# WBZ450 register map
Vendor: Microchip
Registers are 32-bit, read-write, reset 0x0 unless marked. A register's access mark holds for its fields unless they carry their own. Addresses are absolute, and some are shared; only a register's first bit layout is shown; [hi:lo] are bit positions; {n}, {i} and the like mark numbered series; 'fields as' and 'values as' point back to an identical list.

## DMAC
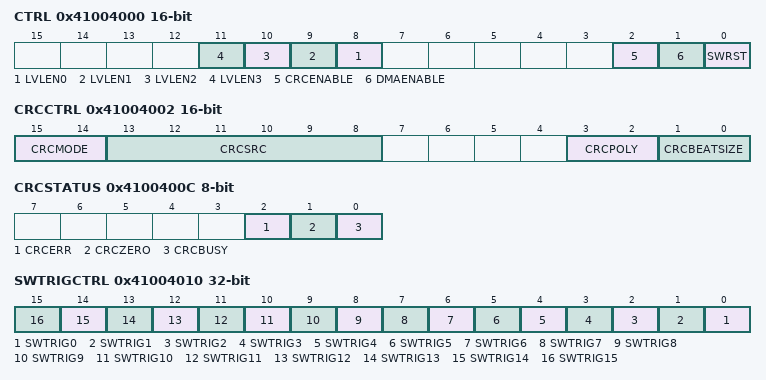
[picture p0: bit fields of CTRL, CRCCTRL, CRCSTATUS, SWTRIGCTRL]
0x41004000 CTRL 16-bit
  [n+8] LVLEN{n} (n=0..3) — Priority Level {n} Enable
  [2] CRCENABLE
  [1] DMAENABLE
  [0] SWRST — Software Reset
0x41004002 CRCCTRL 16-bit
  [15:14] CRCMODE — CRC Operating Mode
    0=DEFAULT (Default operating mode); 2=CRCMON (Memory CRC monitor operating mode); 3=CRCGEN (Memory CRC generation operating mode)
  [13:8] CRCSRC — CRC Input Source
    0=DISABLE (CRC Disabled); 1=IO (I/O interface)
  [3:2] CRCPOLY — CRC Polynomial Type
    0=CRC16 (CRC-16 (CRC-CCITT)); 1=CRC32 (CRC32 (IEEE 802.3))
  [1:0] CRCBEATSIZE
    0=BYTE (8-bit bus transfer); 1=HWORD (16-bit bus transfer); 2=WORD (32-bit bus transfer)
0x41004004 CRCDATAIN
  [31:0] CRCDATAIN — CRC Data Input
0x41004008 CRCCHKSUM
  [31:0] CRCCHKSUM — CRC Checksum
0x4100400C CRCSTATUS 8-bit
  [2] CRCERR — CRC Error
  [1] CRCZERO
  [0] CRCBUSY — CRC Module Busy
0x4100400D DBGCTRL 8-bit
  [0] DBGRUN — Debug Run
0x41004010 SWTRIGCTRL
  [n] SWTRIG{n} (n=0..15) — Channel {n} Software Trigger
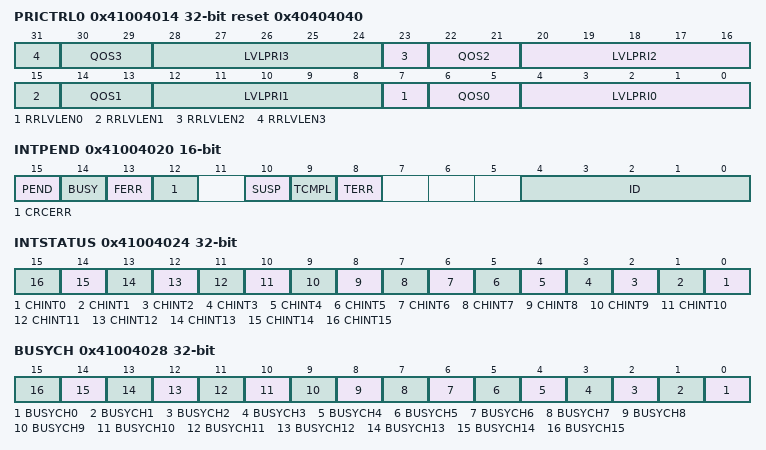
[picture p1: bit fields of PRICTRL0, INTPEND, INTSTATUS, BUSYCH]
0x41004014 PRICTRL0 reset 0x40404040
  [8n+7] RRLVLEN{n} (n=0..3) — Level {n} Round-Robin Scheduling Enable
  [8n+6:8n+5] QOS{n} (n=0..3) — Level {n} Quality of Service
    0=REGULAR (Regular delivery); 1=SHORTAGE (Bandwidth shortage); 2=SENSITIVE (Latency sensitive); 3=CRITICAL (Latency critical)
  [8n+4:8n] LVLPRI{n} (n=0..3) — Level {n} Channel Priority Number
0x41004020 INTPEND 16-bit
  [15] PEND — Pending
  [14] BUSY
  [13] FERR — Fetch Error
  [12] CRCERR — CRC Error
  [10] SUSP — Channel Suspend
  [9] TCMPL — Transfer Complete
  [8] TERR — Transfer Error
  [4:0] ID — Channel ID
0x41004024 INTSTATUS ro
  [n] CHINT{n} (n=0..15) — Channel {n} Pending Interrupt
0x41004028 BUSYCH ro
  [n] BUSYCH{n} (n=0..15) — Busy Channel {n}
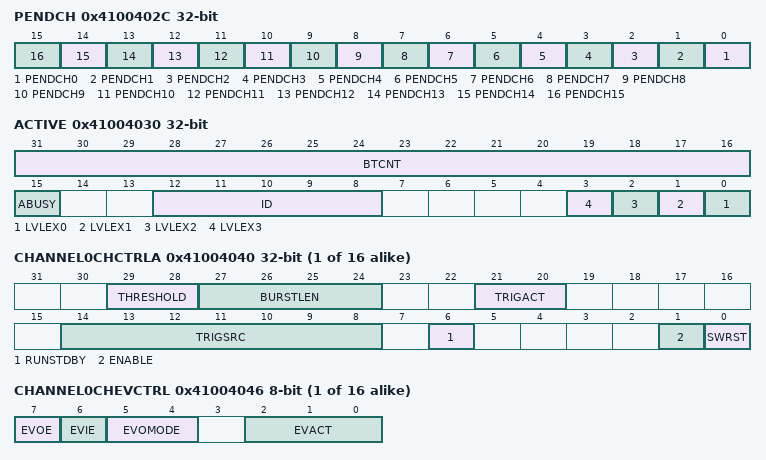
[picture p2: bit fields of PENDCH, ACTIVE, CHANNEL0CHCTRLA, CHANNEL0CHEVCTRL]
0x4100402C PENDCH ro
  [n] PENDCH{n} (n=0..15) — Pending Channel {n}
0x41004030 ACTIVE ro
  [31:16] BTCNT — Active Channel Block Transfer Count
  [15] ABUSY — Active Channel Busy
  [12:8] ID — Active Channel ID
  [n] LVLEX{n} (n=0..3) — Level {n} Channel Trigger Request Executing
0x41004034 BASEADDR
  [31:0] BASEADDR — Descriptor Memory Base Address
0x41004038 WRBADDR
  [31:0] WRBADDR — Write-Back Memory Base Address
{0x41004040+0x10*i} CHANNEL{i}CHCTRLA (i=0..15)
  [29:28] THRESHOLD — FIFO Threshold
    0=1BEAT (Destination write starts after each beat source address read); 1=2BEATS (Destination write starts after 2-beats source address read); 2=4BEATS (Destination write starts after 4-beats source address read); 3=8BEATS (Destination write starts after 8-beats source address read)
  [27:24] BURSTLEN — Burst Length
    0=SINGLE (Single-beat burst length); {v}={v+1}BEAT ({v+1}-beats burst length) (v=1..15)
  [21:20] TRIGACT — Trigger Action
    0=BLOCK (One trigger required for each block transfer); 2=BURST (One trigger required for each burst transfer); 3=TRANSACTION (One trigger required for each transaction)
  [14:8] TRIGSRC — Trigger Source
    0=DISABLE (Only software/event triggers)
  [6] RUNSTDBY — Channel Run in Standby
  [1] ENABLE — Channel Enable
  [0] SWRST — Channel Software Reset
{0x41004044+0x10*i} CHANNEL{i}CHCTRLB 8-bit (i=0..15)
  [1:0] CMD — Software Command
    0=NOACT (No action); 1=SUSPEND (Channel suspend operation); 2=RESUME (Channel resume operation)
{0x41004045+0x10*i} CHANNEL{i}CHPRILVL 8-bit (i=0..15)
  [1:0] PRILVL — Channel Priority Level
    0=LVL0 (Channel Priority Level 0 (Lowest Level)); 1=LVL1 (Channel Priority Level 1); 2=LVL2 (Channel Priority Level 2); 3=LVL3 (Channel Priority Level 3 (Highest Level))
{0x41004046+0x10*i} CHANNEL{i}CHEVCTRL 8-bit (i=0..15)
  [7] EVOE — Channel Event Output Enable
  [6] EVIE — Channel Event Input Enable
  [5:4] EVOMODE — Channel Event Output Mode
    0=DEFAULT (Block event output selection. Refer to BTCTRL.EVOSEL for available selections.); 1=TRIGACT (Ongoing trigger action)
  [2:0] EVACT — Channel Event Input Action
    0=NOACT (No action); 1=TRIG (Transfer and periodic transfer trigger); 2=CTRIG (Conditional transfer trigger); 3=CBLOCK (Conditional block transfer); 4=SUSPEND (Channel suspend operation); 5=RESUME (Channel resume operation); 6=SSKIP (Skip next block suspend action); 7=INCPRI (Increase priority)
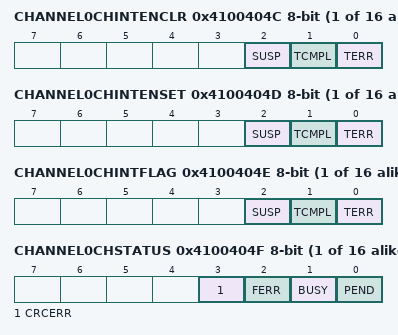
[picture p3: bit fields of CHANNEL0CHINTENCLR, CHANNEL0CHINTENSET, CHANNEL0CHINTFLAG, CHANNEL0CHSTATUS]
{0x4100404C+0x10*i} CHANNEL{i}CHINTENCLR 8-bit (i=0..15)
  [2] SUSP — Channel Suspend Interrupt Enable
  [1] TCMPL — Channel Transfer Complete Interrupt Enable
  [0] TERR — Channel Transfer Error Interrupt Enable
{0x4100404D+0x10*i} CHANNEL{i}CHINTENSET 8-bit (i=0..15)
  fields as CHANNEL0CHINTENCLR
{0x4100404E+0x10*i} CHANNEL{i}CHINTFLAG 8-bit (i=0..15)
  [2] SUSP — Channel Suspend
  [1] TCMPL — Channel Transfer Complete
  [0] TERR — Channel Transfer Error
{0x4100404F+0x10*i} CHANNEL{i}CHSTATUS 8-bit (i=0..15)
  [3] CRCERR — Channel CRC Error
  [2] FERR — Channel Fetch Error
  [1] BUSY — Channel Busy
  [0] PEND — Channel Pending
